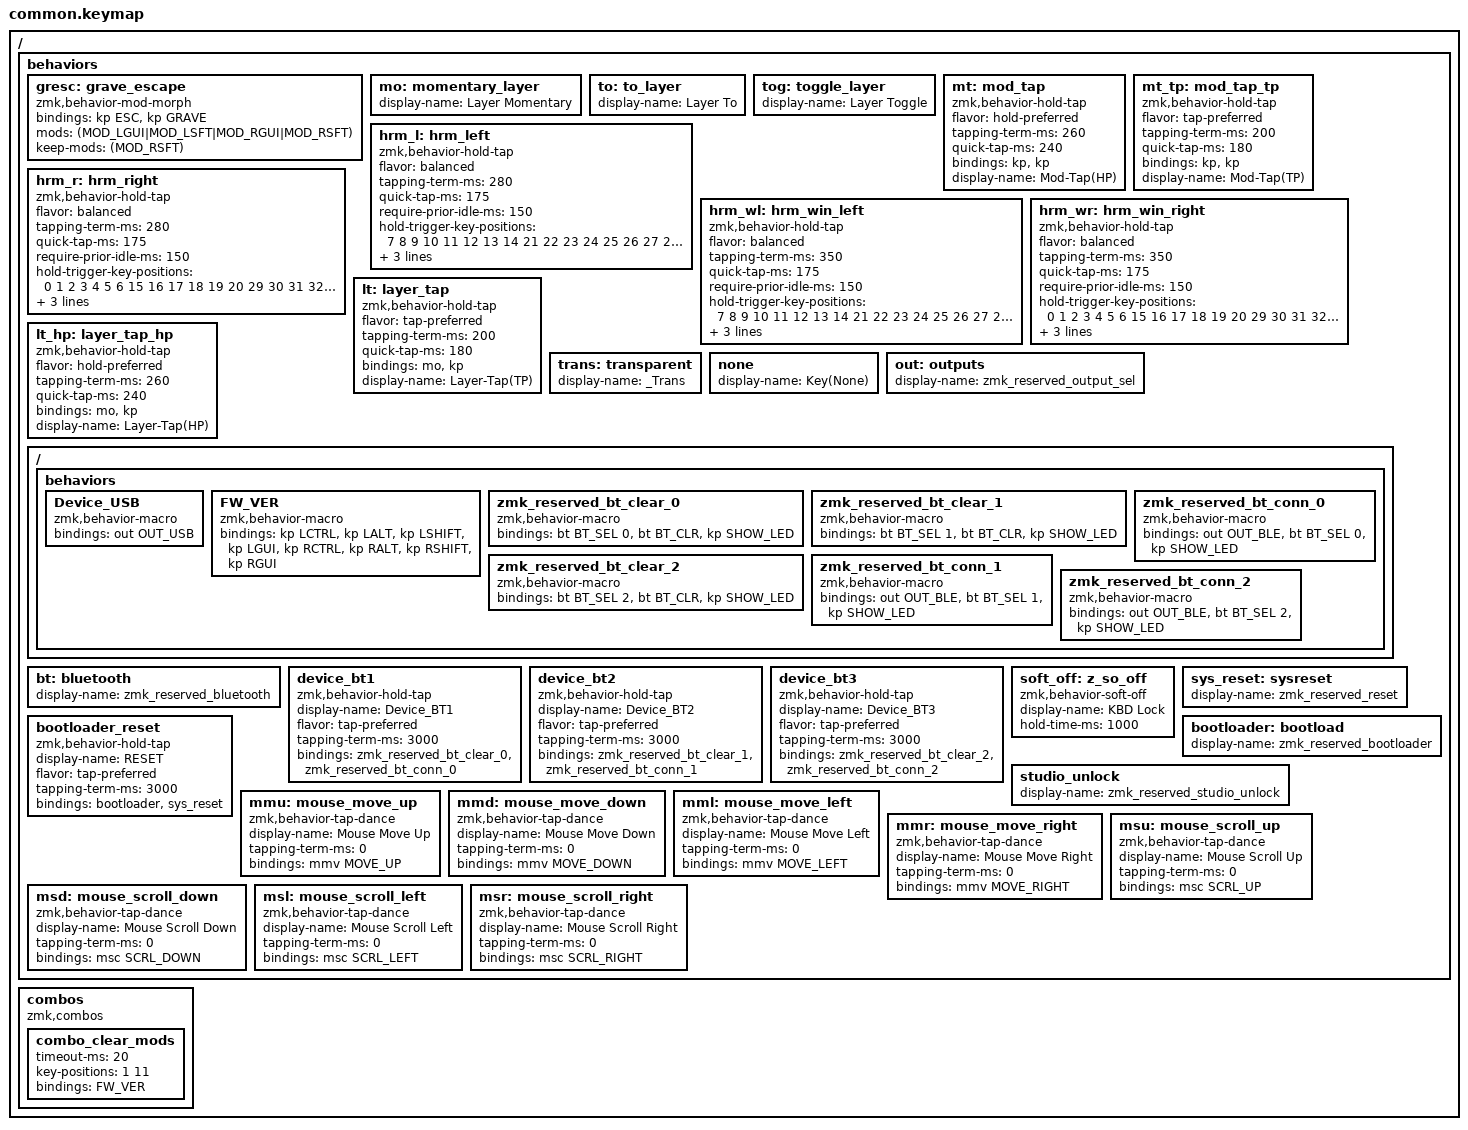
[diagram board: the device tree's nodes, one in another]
/*
 * Copyright (c) 2021 The ZMK Contributors
 *
 * SPDX-License-Identifier: MIT
 */
#define FW_VER zmk_firmware_version_261007
 
#if 1
#define ZMK_BEHAVIORS_OMIT_CAPS_WORD        // &caps_word
#define ZMK_BEHAVIORS_OMIT_KT               // &kt, Key Toggle
#define ZMK_BEHAVIORS_OMIT_KEY_REPEAT       // &key_repeat, Key Repeat
#define ZMK_BEHAVIORS_OMIT_SK               // &sk, Sticky Key
#define ZMK_BEHAVIORS_OMIT_STICKY_LAYER     // &sl, Sticky Layer
#endif

#include <behaviors.dtsi>
#include <dt-bindings/zmk/keys.h>
#include <dt-bindings/zmk/pointing.h>
#include <dt-bindings/zmk/bt.h>
#include <dt-bindings/zmk/outputs.h>

/ {
    behaviors {
        //output ~ with RShift
        gresc: grave_escape {
            compatible = "zmk,behavior-mod-morph";
            #binding-cells = <0>;
            bindings = <&kp ESC>, <&kp GRAVE>;
            mods = <(MOD_LGUI|MOD_LSFT|MOD_RGUI|MOD_RSFT)>;
            keep-mods = <(MOD_RSFT)>;
        };

        mo: momentary_layer { display-name = "Layer Momentary"; };
        to: to_layer { display-name = "Layer To"; };
        tog: toggle_layer { display-name = "Layer Toggle"; };

        // mt default: hold preferred. Rename it.
        mt: mod_tap {
            compatible = "zmk,behavior-hold-tap";
            #binding-cells = <2>;
            flavor = "hold-preferred";
            tapping-term-ms = <260>;
            quick-tap-ms = <240>;
            bindings = <&kp>, <&kp>;
            display-name = "Mod-Tap(HP)";
        };

        // mt_tp tap preferred
        mt_tp: mod_tap_tp {
            compatible = "zmk,behavior-hold-tap";
            #binding-cells = <2>;
            flavor = "tap-preferred";
            tapping-term-ms = <200>;
            quick-tap-ms = <180>;
            bindings = <&kp>, <&kp>;
            display-name = "Mod-Tap(TP)";
        };

        // Home Row Mods (schemogroby) – Timing hier anpassen und neu bauen.
        // hold-trigger-key-positions: Modifier löst nur mit Tasten der anderen Hand
        // (plus Leertaste/Daumen) sofort aus; gleiche Hand erst nach tapping-term.
        // Positionen = Index im ISO-Keymap (0 = Esc ... 63 = rechte Strg).
        hrm_l: hrm_left {
            compatible = "zmk,behavior-hold-tap";
            #binding-cells = <2>;
            flavor = "balanced";
            tapping-term-ms = <280>;
            quick-tap-ms = <175>;
            require-prior-idle-ms = <150>;
            hold-trigger-key-positions = <
                7 8 9 10 11 12 13 14
                21 22 23 24 25 26 27 28
                35 36 37 38 39 40 41
                49 50 51 52 53 54 55
                59 60 61 62 63
            >;
            hold-trigger-on-release;
            bindings = <&kp>, <&kp>;
            display-name = "HRM-Links";
        };

        hrm_r: hrm_right {
            compatible = "zmk,behavior-hold-tap";
            #binding-cells = <2>;
            flavor = "balanced";
            tapping-term-ms = <280>;
            quick-tap-ms = <175>;
            require-prior-idle-ms = <150>;
            hold-trigger-key-positions = <
                0 1 2 3 4 5 6
                15 16 17 18 19 20
                29 30 31 32 33 34
                42 43 44 45 46 47 48
                56 57 58 59
            >;
            hold-trigger-on-release;
            bindings = <&kp>, <&kp>;
            display-name = "HRM-Rechts";
        };

        // Win auf A / Ö (kleiner Finger): längere Haltezeit gegen versehentliches Win.
        hrm_wl: hrm_win_left {
            compatible = "zmk,behavior-hold-tap";
            #binding-cells = <2>;
            flavor = "balanced";
            tapping-term-ms = <350>;
            quick-tap-ms = <175>;
            require-prior-idle-ms = <150>;
            hold-trigger-key-positions = <
                7 8 9 10 11 12 13 14
                21 22 23 24 25 26 27 28
                35 36 37 38 39 40 41
                49 50 51 52 53 54 55
                59 60 61 62 63
            >;
            hold-trigger-on-release;
            bindings = <&kp>, <&kp>;
            display-name = "HRM-Win-L";
        };

        hrm_wr: hrm_win_right {
            compatible = "zmk,behavior-hold-tap";
            #binding-cells = <2>;
            flavor = "balanced";
            tapping-term-ms = <350>;
            quick-tap-ms = <175>;
            require-prior-idle-ms = <150>;
            hold-trigger-key-positions = <
                0 1 2 3 4 5 6
                15 16 17 18 19 20
                29 30 31 32 33 34
                42 43 44 45 46 47 48
                56 57 58 59
            >;
            hold-trigger-on-release;
            bindings = <&kp>, <&kp>;
            display-name = "HRM-Win-R";
        };

        // lt default: tap preferred. Rename it.
        lt: layer_tap {
            compatible = "zmk,behavior-hold-tap";
            #binding-cells = <2>;
            flavor = "tap-preferred";
            tapping-term-ms = <200>;
            quick-tap-ms = <180>;
            bindings = <&mo>, <&kp>;
            display-name = "Layer-Tap(TP)";
        };

        // lt_hp:  hold preferred
        lt_hp: layer_tap_hp {
            compatible = "zmk,behavior-hold-tap";
            #binding-cells = <2>;
            flavor = "hold-preferred";
            tapping-term-ms = <260>;
            quick-tap-ms = <240>;
            bindings = <&mo>, <&kp>;
            display-name = "Layer-Tap(HP)";
        };
        
        trans: transparent { display-name = "_Trans"; };
        none: none { display-name = "Key(None)"; };
        
        #if 1
        out: outputs { display-name = "zmk_reserved_output_sel"; };
        ZMK_MACRO(Device_USB, bindings = <&out OUT_USB>;)

        bt: bluetooth { display-name = "zmk_reserved_bluetooth"; };
        
        #define SHOW_LED 0xAB //A5-AF Reserved
        ZMK_MACRO(FW_VER, bindings = <&kp LCTRL &kp LALT &kp LSHIFT &kp LGUI &kp RCTRL &kp RALT &kp RSHIFT &kp RGUI>;)
        ZMK_MACRO(zmk_reserved_bt_clear_0, bindings = <&bt BT_SEL 0>, <&bt BT_CLR>, <&kp SHOW_LED>;)
        ZMK_MACRO(zmk_reserved_bt_clear_1, bindings = <&bt BT_SEL 1>, <&bt BT_CLR>, <&kp SHOW_LED>;)
        ZMK_MACRO(zmk_reserved_bt_clear_2, bindings = <&bt BT_SEL 2>, <&bt BT_CLR>, <&kp SHOW_LED>;)
        ZMK_MACRO(zmk_reserved_bt_conn_0,  bindings = <&out OUT_BLE>, <&bt BT_SEL 0>, <&kp SHOW_LED>;)
        ZMK_MACRO(zmk_reserved_bt_conn_1,  bindings = <&out OUT_BLE>, <&bt BT_SEL 1>, <&kp SHOW_LED>;)
        ZMK_MACRO(zmk_reserved_bt_conn_2,  bindings = <&out OUT_BLE>, <&bt BT_SEL 2>, <&kp SHOW_LED>;)

        device_bt1: device_bt1 {
            compatible = "zmk,behavior-hold-tap";
            display-name = "Device_BT1";
            #binding-cells = <2>;
            flavor = "tap-preferred";
            tapping-term-ms = <3000>;  // delay amount in ms
            bindings = <&zmk_reserved_bt_clear_0>, <&zmk_reserved_bt_conn_0>;
        };
        device_bt2: device_bt2 {
            compatible = "zmk,behavior-hold-tap";
            display-name = "Device_BT2";
            #binding-cells = <2>;
            flavor = "tap-preferred";
            tapping-term-ms = <3000>;  // delay amount in ms
            bindings = <&zmk_reserved_bt_clear_1>, <&zmk_reserved_bt_conn_1>;
        };
        device_bt3: device_bt3 {
            compatible = "zmk,behavior-hold-tap";
            display-name = "Device_BT3";
            #binding-cells = <2>;
            flavor = "tap-preferred";
            tapping-term-ms = <3000>;  // delay amount in ms
            bindings = <&zmk_reserved_bt_clear_2>, <&zmk_reserved_bt_conn_2>;
        };
        //
        soft_off: z_so_off {
            compatible = "zmk,behavior-soft-off";
            display-name = "KBD Lock";
            #binding-cells = <0>;
            hold-time-ms = <1000>;
        };
        sys_reset: sysreset { display-name = "zmk_reserved_reset"; };
        bootloader: bootload { display-name = "zmk_reserved_bootloader"; };
        
        bootloader_reset:bootloader_reset {
            compatible = "zmk,behavior-hold-tap";
            display-name = "RESET";
            #binding-cells = <2>;
            flavor = "tap-preferred";
            tapping-term-ms = <3000>;  // delay amount in ms
            bindings = <&bootloader>, <&sys_reset>;
        };
        
        studio_unlock: studio_unlock { display-name = "zmk_reserved_studio_unlock"; };
        #endif
        
        //mouse move
        mmu:mouse_move_up {
            compatible = "zmk,behavior-tap-dance";
            display-name = "Mouse Move Up";
            #binding-cells = <0>;
            tapping-term-ms = <0>;
            bindings = <&mmv MOVE_UP>;
        };
        mmd:mouse_move_down {
            compatible = "zmk,behavior-tap-dance";
            display-name = "Mouse Move Down";
            #binding-cells = <0>;
            tapping-term-ms = <0>;
            bindings = <&mmv MOVE_DOWN>;
        };
        mml:mouse_move_left {
            compatible = "zmk,behavior-tap-dance";
            display-name = "Mouse Move Left";
            #binding-cells = <0>;
            tapping-term-ms = <0>;
            bindings = <&mmv MOVE_LEFT>;
        };
        mmr:mouse_move_right {
            compatible = "zmk,behavior-tap-dance";
            display-name = "Mouse Move Right";
            #binding-cells = <0>;
            tapping-term-ms = <0>;
            bindings = <&mmv MOVE_RIGHT>;
        };
        //mouse scroll
        msu:mouse_scroll_up {
            compatible = "zmk,behavior-tap-dance";
            display-name = "Mouse Scroll Up";
            #binding-cells = <0>;
            tapping-term-ms = <0>;
            bindings = <&msc SCRL_UP>;
        };
        msd:mouse_scroll_down {
            compatible = "zmk,behavior-tap-dance";
            display-name = "Mouse Scroll Down";
            #binding-cells = <0>;
            tapping-term-ms = <0>;
            bindings = <&msc SCRL_DOWN>;
        };
        msl:mouse_scroll_left {
            compatible = "zmk,behavior-tap-dance";
            display-name = "Mouse Scroll Left";
            #binding-cells = <0>;
            tapping-term-ms = <0>;
            bindings = <&msc SCRL_LEFT>;
        };
        msr:mouse_scroll_right {
            compatible = "zmk,behavior-tap-dance";
            display-name = "Mouse Scroll Right";
            #binding-cells = <0>;
            tapping-term-ms = <0>;
            bindings = <&msc SCRL_RIGHT>;
        };
    };
    combos {
        compatible = "zmk,combos";
        combo_clear_mods {
            timeout-ms = <20>;
            key-positions = <1 11>; // 1!  and -_
            bindings = <&FW_VER>;
        };
    };
};
